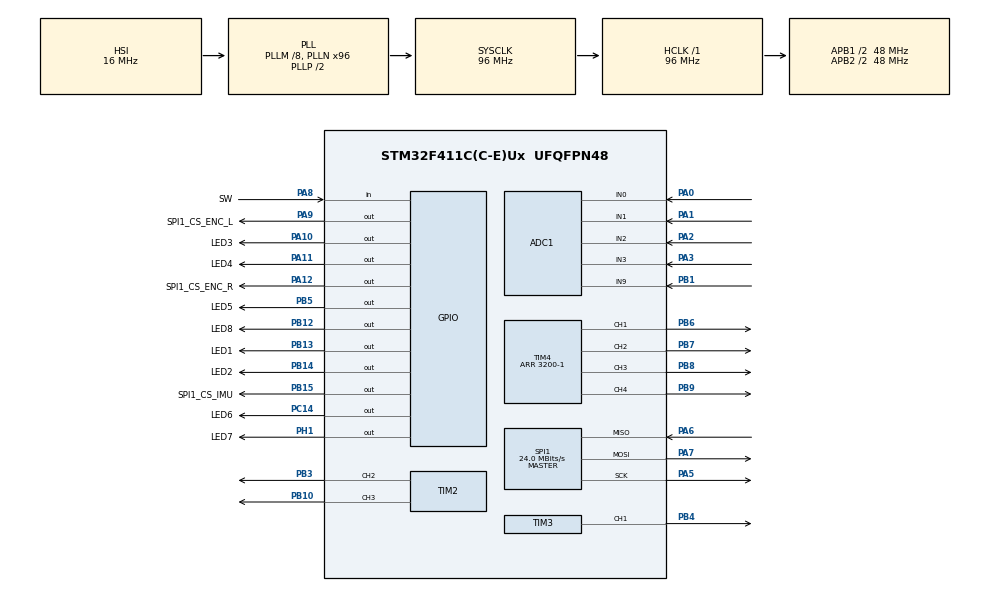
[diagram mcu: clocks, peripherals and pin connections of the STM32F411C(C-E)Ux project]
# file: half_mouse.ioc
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ADC1.Channel-0\#ChannelRegularConversion=ADC_CHANNEL_0
ADC1.NbrOfConversionFlag=1
ADC1.Rank-0\#ChannelRegularConversion=1
ADC1.SamplingTime-0\#ChannelRegularConversion=ADC_SAMPLETIME_3CYCLES
ADC1.master=1
Mcu.Family=STM32F4
Mcu.Name=STM32F411C(C-E)Ux
Mcu.Package=UFQFPN48
NVIC.PriorityGroup=NVIC_PRIORITYGROUP_4
NVIC.TIM1_BRK_TIM9_IRQn=true\:0\:0\:false\:false\:true\:false\:true\:true
NVIC.TIM1_UP_TIM10_IRQn=true\:0\:0\:false\:false\:true\:true\:true\:true
PA0-WKUP.Signal=ADCx_IN0
PA1.Signal=ADCx_IN1
PA10.GPIO_Label=LED3
PA10.Signal=GPIO_Output
PA11.GPIO_Label=LED4
PA11.Signal=GPIO_Output
PA12.GPIO_Label=SPI1_CS_ENC_R
PA12.Signal=GPIO_Output
PA13.Mode=Serial_Wire
PA13.Signal=SYS_JTMS-SWDIO
PA14.Mode=Serial_Wire
PA14.Signal=SYS_JTCK-SWCLK
PA2.Signal=ADCx_IN2
PA3.Signal=ADCx_IN3
PA5.Mode=Full_Duplex_Master
PA5.Signal=SPI1_SCK
PA6.Mode=Full_Duplex_Master
PA6.Signal=SPI1_MISO
PA7.Mode=Full_Duplex_Master
PA7.Signal=SPI1_MOSI
PA8.GPIO_Label=SW
PA8.Signal=GPIO_Input
PA9.GPIO_Label=SPI1_CS_ENC_L
PA9.Signal=GPIO_Output
PB1.Signal=ADCx_IN9
PB10.Signal=S_TIM2_CH3
PB12.GPIO_Label=LED8
PB12.Signal=GPIO_Output
PB13.GPIO_Label=LED1
PB13.Signal=GPIO_Output
PB14.GPIO_Label=LED2
PB14.Signal=GPIO_Output
PB15.GPIO_Label=SPI1_CS_IMU
PB15.Signal=GPIO_Output
PB3.Signal=S_TIM2_CH2
PB4.Signal=S_TIM3_CH1
PB5.GPIO_Label=LED5
PB5.Signal=GPIO_Output
PB6.Signal=S_TIM4_CH1
PB7.Signal=S_TIM4_CH2
PB8.Signal=S_TIM4_CH3
PB9.Signal=S_TIM4_CH4
PC14-OSC32_IN.GPIO_Label=LED6
PC14-OSC32_IN.Signal=GPIO_Output
PH1\ -\ OSC_OUT.GPIO_Label=LED7
PH1\ -\ OSC_OUT.Signal=GPIO_Output
ProjectManager.HeapSize=0x200
ProjectManager.StackSize=0x400
ProjectManager.TargetToolchain=Makefile
RCC.48MHZClocksFreq_Value=48000000
RCC.AHBFreq_Value=96000000
RCC.APB1CLKDivider=RCC_HCLK_DIV2
RCC.APB1Freq_Value=48000000
RCC.APB1TimFreq_Value=96000000
RCC.APB2CLKDivider=RCC_HCLK_DIV2
RCC.APB2Freq_Value=48000000
RCC.APB2TimFreq_Value=96000000
RCC.CortexFreq_Value=96000000
RCC.HCLKFreq_Value=96000000
RCC.HSE_VALUE=25000000
RCC.HSI_VALUE=16000000
RCC.LSE_VALUE=32768
RCC.PLLM=8
RCC.PLLN=96
RCC.SYSCLKFreq_VALUE=96000000
RCC.SYSCLKSource=RCC_SYSCLKSOURCE_PLLCLK
RCC.VCOOutputFreq_Value=192000000
SH.ADCx_IN0.0=ADC1_IN0,IN0
SH.ADCx_IN1.0=ADC1_IN1,IN1
SH.ADCx_IN2.0=ADC1_IN2,IN2
SH.ADCx_IN3.0=ADC1_IN3,IN3
SH.ADCx_IN9.0=ADC1_IN9,IN9
SH.S_TIM2_CH2.0=TIM2_CH2,PWM Generation2 CH2
SH.S_TIM2_CH3.0=TIM2_CH3,PWM Generation3 CH3
SH.S_TIM3_CH1.0=TIM3_CH1,PWM Generation1 CH1
SH.S_TIM4_CH1.0=TIM4_CH1,PWM Generation1 CH1
SH.S_TIM4_CH2.0=TIM4_CH2,PWM Generation2 CH2
SH.S_TIM4_CH3.0=TIM4_CH3,PWM Generation3 CH3
SH.S_TIM4_CH4.0=TIM4_CH4,PWM Generation4 CH4
SPI1.CalculateBaudRate=24.0 MBits/s
SPI1.Direction=SPI_DIRECTION_2LINES
SPI1.Mode=SPI_MODE_MASTER
SPI1.VirtualType=VM_MASTER
TIM1.Period=1000-1
TIM1.Prescaler=96-1
TIM2.Channel-PWM\ Generation2\ CH2=TIM_CHANNEL_2
TIM2.Channel-PWM\ Generation3\ CH3=TIM_CHANNEL_3
TIM3.Channel-PWM\ Generation1\ CH1=TIM_CHANNEL_1
TIM3.Period=1000-1
TIM3.Prescaler=96-1
TIM4.Channel-PWM\ Generation1\ CH1=TIM_CHANNEL_1
TIM4.Channel-PWM\ Generation2\ CH2=TIM_CHANNEL_2
TIM4.Channel-PWM\ Generation3\ CH3=TIM_CHANNEL_3
TIM4.Channel-PWM\ Generation4\ CH4=TIM_CHANNEL_4
TIM4.Period=3200-1
VP_TIM1_VS_ClockSourceINT.Mode=Internal
board=custom

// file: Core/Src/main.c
/* USER CODE BEGIN Header */
/**
 ******************************************************************************
 * @file           : main.c
 * @brief          : Main program body
 ******************************************************************************
 * @attention
 *
 * Copyright (c) 2023 STMicroelectronics.
 * All rights reserved.
 *
 * This software is licensed under terms that can be found in the LICENSE file
 * in the root directory of this software component.
 * If no LICENSE file comes with this software, it is provided AS-IS.
 *
 ******************************************************************************
 */
/* USER CODE END Header */
#include "main.h"
#include "adc.h"
#include "spi.h"
#include "tim.h"
#include "gpio.h"

void SystemClock_Config(void);

int main(void)
{

  /* MCU Configuration--------------------------------------------------------*/

  /* Reset of all peripherals, Initializes the Flash interface and the Systick. */
  HAL_Init();

  /* Configure the system clock */
  SystemClock_Config();

  /* Initialize all configured peripherals */
  MX_GPIO_Init();
  MX_SPI1_Init();
  MX_ADC1_Init();
  MX_TIM1_Init();
  MX_TIM2_Init();
  MX_TIM3_Init();
  MX_TIM4_Init();
  /* USER CODE BEGIN 2 */
  // PWM_Start(&motorL);
  // PWM_Start(&motorR);
  HAL_TIM_PWM_Start(&htim3, TIM_CHANNEL_1); // speaker
  // HAL_TIM_PWM_Start(&htim2, TIM_CHANNEL_2); // ir_led side
  // HAL_TIM_PWM_Start(&htim2, TIM_CHANNEL_3); // ir_led front
  Write_GPIO(SIDE_RIGHT_LED, 1);
  Write_GPIO(FRONT_RIGHT_LED, 1);
  Write_GPIO(FRONT_LEFT_LED, 1);
  Write_GPIO(SIDE_LEFT_LED, 1);

  Write_GPIO(BACK_RIGHT_RED_LED, 1);
  Write_GPIO(BACK_RIGHT_ORANGE_LED, 1);
  Write_GPIO(BACK_LEFT_RED_LED, 1);
  Write_GPIO(BACK_LEFT_ORANGE_LED, 1);

  __HAL_TIM_SET_COMPARE(&htim3, TIM_CHANNEL_1, 10);
  HAL_Delay(30);
  __HAL_TIM_SET_COMPARE(&htim3, TIM_CHANNEL_1, 0);
  /* USER CODE END 2 */

  /* Infinite loop */
  while (1)
  {

  }
}

void SystemClock_Config(void)
{
  RCC_OscInitTypeDef RCC_OscInitStruct = {0};
  RCC_ClkInitTypeDef RCC_ClkInitStruct = {0};

  /** Configure the main internal regulator output voltage
   */
  __HAL_RCC_PWR_CLK_ENABLE();
  __HAL_PWR_VOLTAGESCALING_CONFIG(PWR_REGULATOR_VOLTAGE_SCALE1);

  /** Initializes the RCC Oscillators according to the specified parameters
   * in the RCC_OscInitTypeDef structure.
   */
  RCC_OscInitStruct.OscillatorType = RCC_OSCILLATORTYPE_HSI;
  RCC_OscInitStruct.HSIState = RCC_HSI_ON;
  RCC_OscInitStruct.HSICalibrationValue = RCC_HSICALIBRATION_DEFAULT;
  RCC_OscInitStruct.PLL.PLLState = RCC_PLL_ON;
  RCC_OscInitStruct.PLL.PLLSource = RCC_PLLSOURCE_HSI;
  RCC_OscInitStruct.PLL.PLLM = 8;
  RCC_OscInitStruct.PLL.PLLN = 96;
  RCC_OscInitStruct.PLL.PLLP = RCC_PLLP_DIV2;
  RCC_OscInitStruct.PLL.PLLQ = 4;
  if (HAL_RCC_OscConfig(&RCC_OscInitStruct) != HAL_OK)
  {
    Error_Handler();
  }

  /** Initializes the CPU, AHB and APB buses clocks
   */
  RCC_ClkInitStruct.ClockType = RCC_CLOCKTYPE_HCLK | RCC_CLOCKTYPE_SYSCLK | RCC_CLOCKTYPE_PCLK1 | RCC_CLOCKTYPE_PCLK2;
  RCC_ClkInitStruct.SYSCLKSource = RCC_SYSCLKSOURCE_PLLCLK;
  RCC_ClkInitStruct.AHBCLKDivider = RCC_SYSCLK_DIV1;
  RCC_ClkInitStruct.APB1CLKDivider = RCC_HCLK_DIV2;
  RCC_ClkInitStruct.APB2CLKDivider = RCC_HCLK_DIV2;

  if (HAL_RCC_ClockConfig(&RCC_ClkInitStruct, FLASH_LATENCY_3) != HAL_OK)
  {
    Error_Handler();
  }
}

void Error_Handler(void)
{
  __disable_irq();
  while (1)
  {
  }
}
